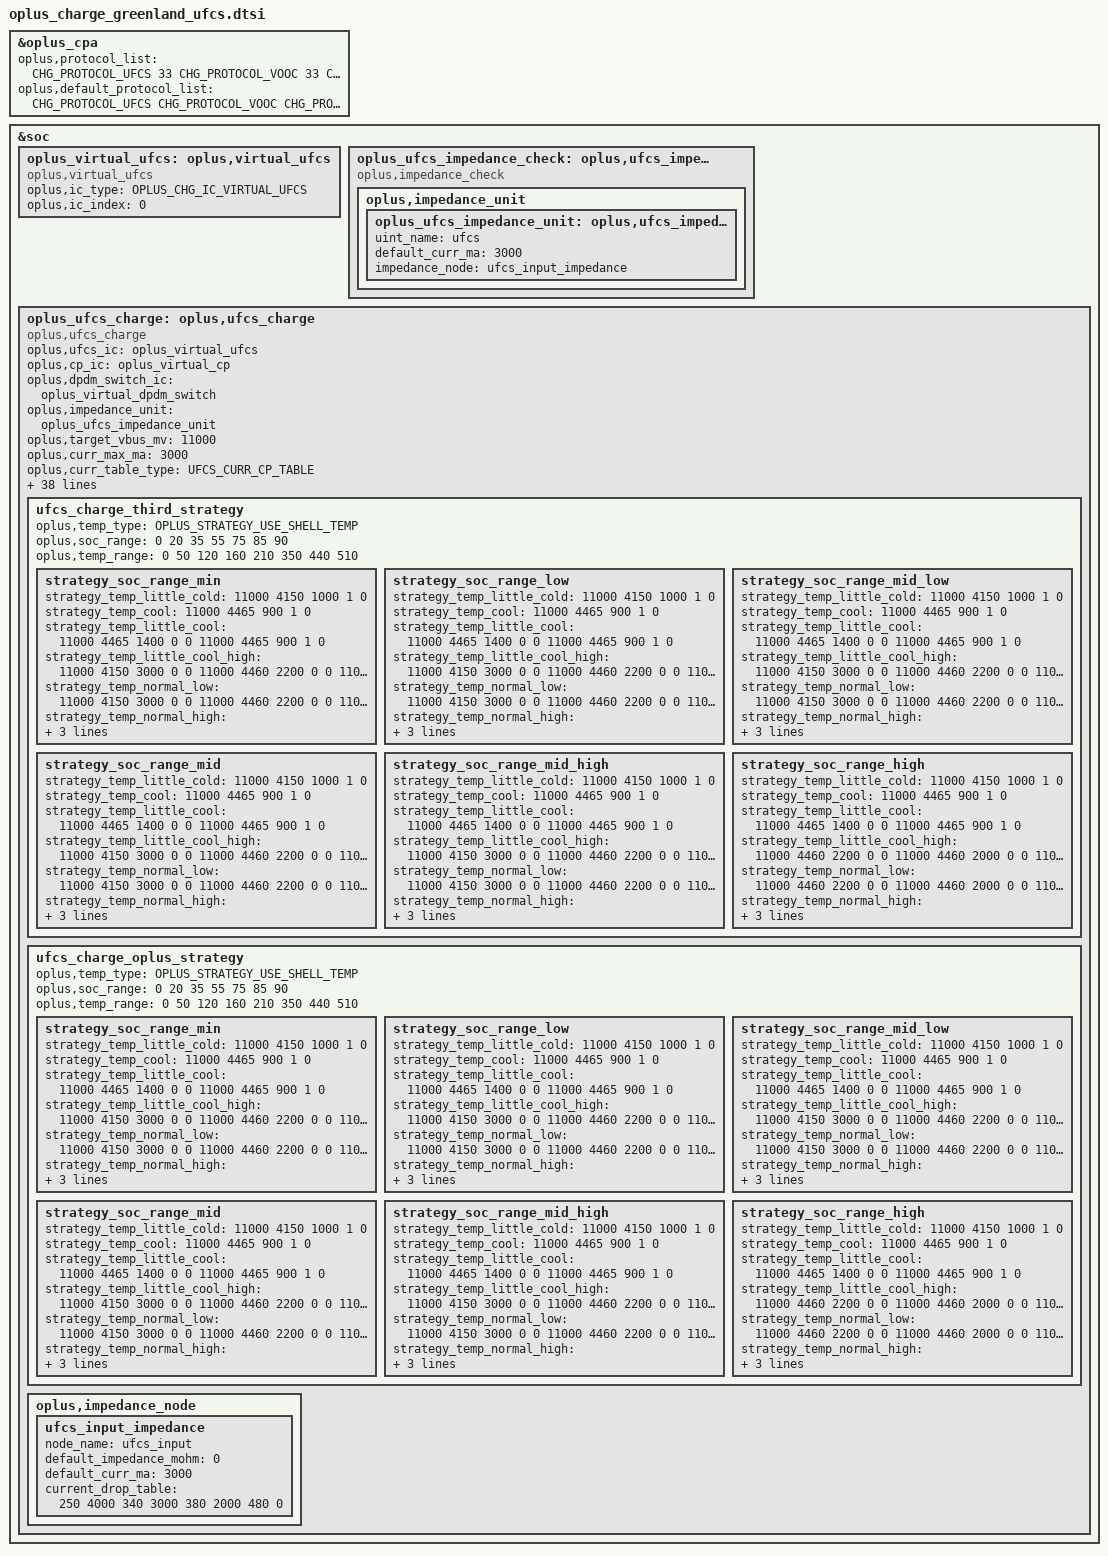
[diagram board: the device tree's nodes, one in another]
&oplus_cpa {
		oplus,protocol_list = <CHG_PROTOCOL_UFCS 33
					CHG_PROTOCOL_VOOC 33
					CHG_PROTOCOL_PPS 33
					CHG_PROTOCOL_PD 18
					CHG_PROTOCOL_QC 18>;
		oplus,default_protocol_list = <CHG_PROTOCOL_UFCS
					CHG_PROTOCOL_VOOC
					CHG_PROTOCOL_PPS
					CHG_PROTOCOL_PD>;
};

&soc {
	oplus_virtual_ufcs: oplus,virtual_ufcs {
		compatible = "oplus,virtual_ufcs";

		oplus,ic_type = <OPLUS_CHG_IC_VIRTUAL_UFCS>;
		oplus,ic_index = <0>;
	};

	oplus_ufcs_impedance_check: oplus,ufcs_impedance_check {
			compatible = "oplus,impedance_check";

			oplus,impedance_unit {
				oplus_ufcs_impedance_unit: oplus,ufcs_impedance_unit {
					uint_name = "ufcs";
					default_curr_ma = <3000>;
					impedance_node = <&ufcs_input_impedance>;
				};
			};
	};

	oplus_ufcs_charge: oplus,ufcs_charge {
		compatible = "oplus,ufcs_charge";
		oplus,ufcs_ic = <&oplus_virtual_ufcs>;
		oplus,cp_ic = <&oplus_virtual_cp>;
		oplus,dpdm_switch_ic = <&oplus_virtual_dpdm_switch>;

		oplus,impedance_unit = <&oplus_ufcs_impedance_unit>;

		oplus,target_vbus_mv = <11000>;
		oplus,curr_max_ma = <3000>;

		oplus,curr_table_type = <UFCS_CURR_CP_TABLE>;
		oplus,high_imp_compensation_setting_mv = <50>;
		oplus,lift_vbus_use_cpvout;
		oplus,plc_strategy-data = <&oplus_ufcs_step_strategy &third_ufcs_simple_strategy>;
		oplus,plc_strategy-names = "default", "third";

		oplus,ufcs_warm_allow_vol = <4000>;
		oplus,ufcs_warm_allow_soc = <50>;
		oplus,ufcs_strategy_normal_current = <3000>;
		oplus,ufcs_over_high_or_low_current = <3000>;
		oplus,ufcs_timeout_third = <25200>;
		oplus,ufcs_timeout_oplus = <25200>;
		oplus,ufcs_ibat_over_third = <7400>;
		oplus,ufcs_ibat_over_oplus = <7400>;
		oplus,ufcs_full_cool_sw_vbat = <4465>;
		oplus,ufcs_full_normal_sw_vbat = <4465>;
		oplus,ufcs_full_normal_hw_vbat = <4475>;
		oplus,ufcs_full_ffc_vbat = <4465>;
		oplus,ufcs_full_warm_vbat = <4130>;
		oplus,ufcs_full_cool_sw_vbat_third = <4465>;
		oplus,ufcs_full_normal_sw_vbat_third= <4465>;
		oplus,ufcs_full_normal_hw_vbat_third = <4475>;
		oplus,ufcs_current_change_timeout = <100>;
		oplus,ufcs_strategy_batt_high_temp = <410 420 430 400 410 420>;
		oplus,ufcs_strategy_high_current = <3000 2000 2000 3000 3000 3000>;
		oplus,ufcs_little_cool_high_temp = <210>;
		oplus_spec,ufcs_low_temp = <50>;
		oplus,curve_strategy_name = "pps_ufcs_curve_v2";
		oplus_spec,ufcs_high_soc = <90>;
		oplus,ufcs_charge_strategy_soc = <0 20 35 50 75 85 90>;
		oplus,ufcs_charge_strategy_temp = <0 50 120 160 350 440 530>;
		oplus,temperature_strategy_name = "cgcl";
		oplus,temperature_strategy_data = <OPLUS_STRATEGY_USE_SHELL_TEMP
						0   420 3000 1 0
						410 440 2000 1 0>;

		ufcs_charge_third_strategy {
			oplus,temp_type = <OPLUS_STRATEGY_USE_SHELL_TEMP>;
			oplus,soc_range = <0 20 35 55 75 85 90>;
			oplus,temp_range = <0 50 120 160 210 350 440 510>;

			strategy_soc_range_min {/* ui_soc: 0%~20% */
				strategy_temp_little_cold = <11000 4150 1000 1 0>;  //0-5
				strategy_temp_cool = <11000 4465 900 1 0>;   //5-12
				strategy_temp_little_cool =	<11000 4465 1400 0 0  //12-16
								11000 4465 900 1 0>;
				strategy_temp_little_cool_high = <11000 4150 3000 0 0  //16-20
								11000 4460 2200 0 0
								11000 4460 2000 0 0
								11000 4460 1500 0 0
								11000 4465 1000 1 0>;
				strategy_temp_normal_low = <11000 4150 3000 0 0 //20-35
								11000 4460 2200 0 0
								11000 4460 2000 0 0
								11000 4460 1500 0 0
								11000 4465 1000 1 0>;
				strategy_temp_normal_high = <11000 4150 3000 0 0  //35-44
								11000 4460 2200 0 0
								11000 4460 2000 0 0
								11000 4460 1500 0 0
								11000 4465 1000 1 0>;
				strategy_temp_warm = <11000 4130 2700 0 0  //44-51
								11000 4130 2200 0 0
								11000 4130 2000 0 0
								11000 4130 1500 0 0
								11000 4130 1000 1 0>;
			};
			strategy_soc_range_low {/* ui_soc: 21%~35% */
				strategy_temp_little_cold = <11000 4150 1000 1 0>;  //0-5
				strategy_temp_cool = <11000 4465 900 1 0>;   //5-12
				strategy_temp_little_cool =	<11000 4465 1400 0 0  //12-16
								11000 4465 900 1 0>;
				strategy_temp_little_cool_high = <11000 4150 3000 0 0  //16-20
								11000 4460 2200 0 0
								11000 4460 2000 0 0
								11000 4460 1500 0 0
								11000 4465 1000 1 0>;
				strategy_temp_normal_low = <11000 4150 3000 0 0 //20-35
								11000 4460 2200 0 0
								11000 4460 2000 0 0
								11000 4460 1500 0 0
								11000 4465 1000 1 0>;
				strategy_temp_normal_high = <11000 4150 3000 0 0  //35-44
								11000 4460 2200 0 0
								11000 4460 2000 0 0
								11000 4460 1500 0 0
								11000 4465 1000 1 0>;
				strategy_temp_warm = <11000 4130 2700 0 0  //44-51
								11000 4130 2200 0 0
								11000 4130 2000 0 0
								11000 4130 1500 0 0
								11000 4130 1000 1 0>;
			};
			strategy_soc_range_mid_low {/* ui_soc: 36%~50% */
				strategy_temp_little_cold = <11000 4150 1000 1 0>;  //0-5
				strategy_temp_cool = <11000 4465 900 1 0>;   //5-12
				strategy_temp_little_cool =	<11000 4465 1400 0 0  //12-16
								11000 4465 900 1 0>;
				strategy_temp_little_cool_high = <11000 4150 3000 0 0  //16-20
								11000 4460 2200 0 0
								11000 4460 2000 0 0
								11000 4460 1500 0 0
								11000 4465 1000 1 0>;
				strategy_temp_normal_low = <11000 4150 3000 0 0 //20-35
								11000 4460 2200 0 0
								11000 4460 2000 0 0
								11000 4460 1500 0 0
								11000 4465 1000 1 0>;
				strategy_temp_normal_high = <11000 4150 3000 0 0  //35-44
								11000 4460 2200 0 0
								11000 4460 2000 0 0
								11000 4460 1500 0 0
								11000 4465 1000 1 0>;
				strategy_temp_warm = <11000 4130 2700 0 0  //44-51
								11000 4130 2200 0 0
								11000 4130 2000 0 0
								11000 4130 1500 0 0
								11000 4130 1000 1 0>;
			};
			strategy_soc_range_mid { /* ui_soc: 51%~75% */
				strategy_temp_little_cold = <11000 4150 1000 1 0>;  //0-5
				strategy_temp_cool = <11000 4465 900 1 0>;   //5-12
				strategy_temp_little_cool =	<11000 4465 1400 0 0  //12-16
								11000 4465 900 1 0>;
				strategy_temp_little_cool_high = <11000 4150 3000 0 0  //16-20
								11000 4460 2200 0 0
								11000 4460 2000 0 0
								11000 4460 1500 0 0
								11000 4465 1000 1 0>;
				strategy_temp_normal_low = <11000 4150 3000 0 0 //20-35
								11000 4460 2200 0 0
								11000 4460 2000 0 0
								11000 4460 1500 0 0
								11000 4465 1000 1 0>;
				strategy_temp_normal_high = <11000 4150 3000 0 0  //35-44
								11000 4460 2200 0 0
								11000 4460 2000 0 0
								11000 4460 1500 0 0
								11000 4465 1000 1 0>;
				strategy_temp_warm = <11000 4130 2700 0 0  //44-51
								11000 4130 2200 0 0
								11000 4130 2000 0 0
								11000 4130 1500 0 0
								11000 4130 1000 1 0>;
			};
			strategy_soc_range_mid_high {/* ui_soc: 76%~85% */
				strategy_temp_little_cold = <11000 4150 1000 1 0>;  //0-5
				strategy_temp_cool = <11000 4465 900 1 0>;   //5-12
				strategy_temp_little_cool =	<11000 4465 1400 0 0  //12-16
								11000 4465 900 1 0>;
				strategy_temp_little_cool_high = <11000 4150 3000 0 0  //16-20
								11000 4460 2200 0 0
								11000 4460 2000 0 0
								11000 4460 1500 0 0
								11000 4465 1000 1 0>;
				strategy_temp_normal_low = <11000 4150 3000 0 0 //20-35
								11000 4460 2200 0 0
								11000 4460 2000 0 0
								11000 4460 1500 0 0
								11000 4465 1000 1 0>;
				strategy_temp_normal_high = <11000 4150 3000 0 0  //35-44
								11000 4460 2200 0 0
								11000 4460 2000 0 0
								11000 4460 1500 0 0
								11000 4465 1000 1 0>;
				strategy_temp_warm = <11000 4130 2700 0 0  //44-51
								11000 4130 2200 0 0
								11000 4130 2000 0 0
								11000 4130 1500 0 0
								11000 4130 1000 1 0>;
			};
			strategy_soc_range_high {/* ui_soc: 86%~95% */
				strategy_temp_little_cold = <11000 4150 1000 1 0>;  //0-5
				strategy_temp_cool = <11000 4465 900 1 0>;   //5-12
				strategy_temp_little_cool =	<11000 4465 1400 0 0  //12-16
								11000 4465 900 1 0>;
				strategy_temp_little_cool_high = <11000 4460 2200 0 0  //16-20
								11000 4460 2000 0 0
								11000 4460 1500 0 0
								11000 4465 1000 1 0>;
				strategy_temp_normal_low = <11000 4460 2200 0 0 //20-35
								11000 4460 2000 0 0
								11000 4460 1500 0 0
								11000 4465 1000 1 0>;
				strategy_temp_normal_high = <11000 4460 2200 0 0  //35-44
								11000 4460 2000 0 0
								11000 4460 1500 0 0
								11000 4465 1000 1 0>;
				strategy_temp_warm = <11000 4130 2200 0 0  //44-51
								11000 4130 2000 0 0
								11000 4130 1500 0 0
								11000 4130 1000 1 0>;
			};
		};

		ufcs_charge_oplus_strategy {
			oplus,temp_type = <OPLUS_STRATEGY_USE_SHELL_TEMP>;
			oplus,soc_range = <0 20 35 55 75 85 90>;
			oplus,temp_range = <0 50 120 160 210 350 440 510>;

			strategy_soc_range_min {
				strategy_temp_little_cold = <11000 4150 1000 1 0>;  //0-5
				strategy_temp_cool = <11000 4465 900 1 0>;   //5-12
				strategy_temp_little_cool =	<11000 4465 1400 0 0  //12-16
								11000 4465 900 1 0>;
				strategy_temp_little_cool_high = <11000 4150 3000 0 0  //16-20
								11000 4460 2200 0 0
								11000 4460 2000 0 0
								11000 4460 1500 0 0
								11000 4465 1000 1 0>;
				strategy_temp_normal_low = <11000 4150 3000 0 0 //20-35
								11000 4460 2200 0 0
								11000 4460 2000 0 0
								11000 4460 1500 0 0
								11000 4465 1000 1 0>;
				strategy_temp_normal_high = <11000 4150 3000 0 0  //35-44
								11000 4460 2200 0 0
								11000 4460 2000 0 0
								11000 4460 1500 0 0
								11000 4465 1000 1 0>;
				strategy_temp_warm = <11000 4130 2700 0 0  //44-51
								11000 4130 2200 0 0
								11000 4130 2000 0 0
								11000 4130 1500 0 0
								11000 4130 1000 1 0>;
			};
			strategy_soc_range_low {
				strategy_temp_little_cold = <11000 4150 1000 1 0>;  //0-5
				strategy_temp_cool = <11000 4465 900 1 0>;   //5-12
				strategy_temp_little_cool =	<11000 4465 1400 0 0  //12-16
								11000 4465 900 1 0>;
				strategy_temp_little_cool_high = <11000 4150 3000 0 0  //16-20
								11000 4460 2200 0 0
								11000 4460 2000 0 0
								11000 4460 1500 0 0
								11000 4465 1000 1 0>;
				strategy_temp_normal_low = <11000 4150 3000 0 0 //20-35
								11000 4460 2200 0 0
								11000 4460 2000 0 0
								11000 4460 1500 0 0
								11000 4465 1000 1 0>;
				strategy_temp_normal_high = <11000 4150 3000 0 0  //35-44
								11000 4460 2200 0 0
								11000 4460 2000 0 0
								11000 4460 1500 0 0
								11000 4465 1000 1 0>;
				strategy_temp_warm = <11000 4130 2700 0 0  //44-51
								11000 4130 2200 0 0
								11000 4130 2000 0 0
								11000 4130 1500 0 0
								11000 4130 1000 1 0>;

			};
			strategy_soc_range_mid_low {
				strategy_temp_little_cold = <11000 4150 1000 1 0>;  //0-5
				strategy_temp_cool = <11000 4465 900 1 0>;   //5-12
				strategy_temp_little_cool =	<11000 4465 1400 0 0  //12-16
								11000 4465 900 1 0>;
				strategy_temp_little_cool_high = <11000 4150 3000 0 0  //16-20
								11000 4460 2200 0 0
								11000 4460 2000 0 0
								11000 4460 1500 0 0
								11000 4465 1000 1 0>;
				strategy_temp_normal_low = <11000 4150 3000 0 0 //20-35
								11000 4460 2200 0 0
								11000 4460 2000 0 0
								11000 4460 1500 0 0
								11000 4465 1000 1 0>;
				strategy_temp_normal_high = <11000 4150 3000 0 0  //35-44
								11000 4460 2200 0 0
								11000 4460 2000 0 0
								11000 4460 1500 0 0
								11000 4465 1000 1 0>;
				strategy_temp_warm = <11000 4130 2700 0 0  //44-51
								11000 4130 2200 0 0
								11000 4130 2000 0 0
								11000 4130 1500 0 0
								11000 4130 1000 1 0>;
			};
			strategy_soc_range_mid {
				strategy_temp_little_cold = <11000 4150 1000 1 0>;  //0-5
				strategy_temp_cool = <11000 4465 900 1 0>;   //5-12
				strategy_temp_little_cool =	<11000 4465 1400 0 0  //12-16
								11000 4465 900 1 0>;
				strategy_temp_little_cool_high = <11000 4150 3000 0 0  //16-20
								11000 4460 2200 0 0
								11000 4460 2000 0 0
								11000 4460 1500 0 0
								11000 4465 1000 1 0>;
				strategy_temp_normal_low = <11000 4150 3000 0 0 //20-35
								11000 4460 2200 0 0
								11000 4460 2000 0 0
								11000 4460 1500 0 0
								11000 4465 1000 1 0>;
				strategy_temp_normal_high = <11000 4150 3000 0 0  //35-44
								11000 4460 2200 0 0
								11000 4460 2000 0 0
								11000 4460 1500 0 0
								11000 4465 1000 1 0>;
				strategy_temp_warm = <11000 4130 2700 0 0  //44-51
								11000 4130 2200 0 0
								11000 4130 2000 0 0
								11000 4130 1500 0 0
								11000 4130 1000 1 0>;
			};
			strategy_soc_range_mid_high {
				strategy_temp_little_cold = <11000 4150 1000 1 0>;  //0-5
				strategy_temp_cool = <11000 4465 900 1 0>;   //5-12
				strategy_temp_little_cool =	<11000 4465 1400 0 0  //12-16
								11000 4465 900 1 0>;
				strategy_temp_little_cool_high = <11000 4150 3000 0 0  //16-20
								11000 4460 2200 0 0
								11000 4460 2000 0 0
								11000 4460 1500 0 0
								11000 4465 1000 1 0>;
				strategy_temp_normal_low = <11000 4150 3000 0 0 //20-35
								11000 4460 2200 0 0
								11000 4460 2000 0 0
								11000 4460 1500 0 0
								11000 4465 1000 1 0>;
				strategy_temp_normal_high = <11000 4150 3000 0 0  //35-44
								11000 4460 2200 0 0
								11000 4460 2000 0 0
								11000 4460 1500 0 0
								11000 4465 1000 1 0>;
				strategy_temp_warm = <11000 4130 2700 0 0  //44-51
								11000 4130 2200 0 0
								11000 4130 2000 0 0
								11000 4130 1500 0 0
								11000 4130 1000 1 0>;
			};
			strategy_soc_range_high {
				strategy_temp_little_cold = <11000 4150 1000 1 0>;  //0-5
				strategy_temp_cool = <11000 4465 900 1 0>;   //5-12
				strategy_temp_little_cool =	<11000 4465 1400 0 0  //12-16
								11000 4465 900 1 0>;
				strategy_temp_little_cool_high = <11000 4460 2200 0 0  //16-20
								11000 4460 2000 0 0
								11000 4460 1500 0 0
								11000 4465 1000 1 0>;
				strategy_temp_normal_low = <11000 4460 2200 0 0 //20-35
								11000 4460 2000 0 0
								11000 4460 1500 0 0
								11000 4465 1000 1 0>;
				strategy_temp_normal_high = <11000 4460 2200 0 0  //35-44
								11000 4460 2000 0 0
								11000 4460 1500 0 0
								11000 4465 1000 1 0>;
				strategy_temp_warm = <11000 4130 2200 0 0  //44-51
								11000 4130 2000 0 0
								11000 4130 1500 0 0
								11000 4130 1000 1 0>;
			};
		};
		oplus,impedance_node {
			ufcs_input_impedance: ufcs_input_impedance {
				node_name = "ufcs_input";
				default_impedance_mohm = <0>;
				default_curr_ma = <3000>;
				current_drop_table = <
					250  4000
					340  3000
					380  2000
					480 0>;
			};
		};
	};
};

//#endif OPLUS_FEATURE_CHG_BASIC

